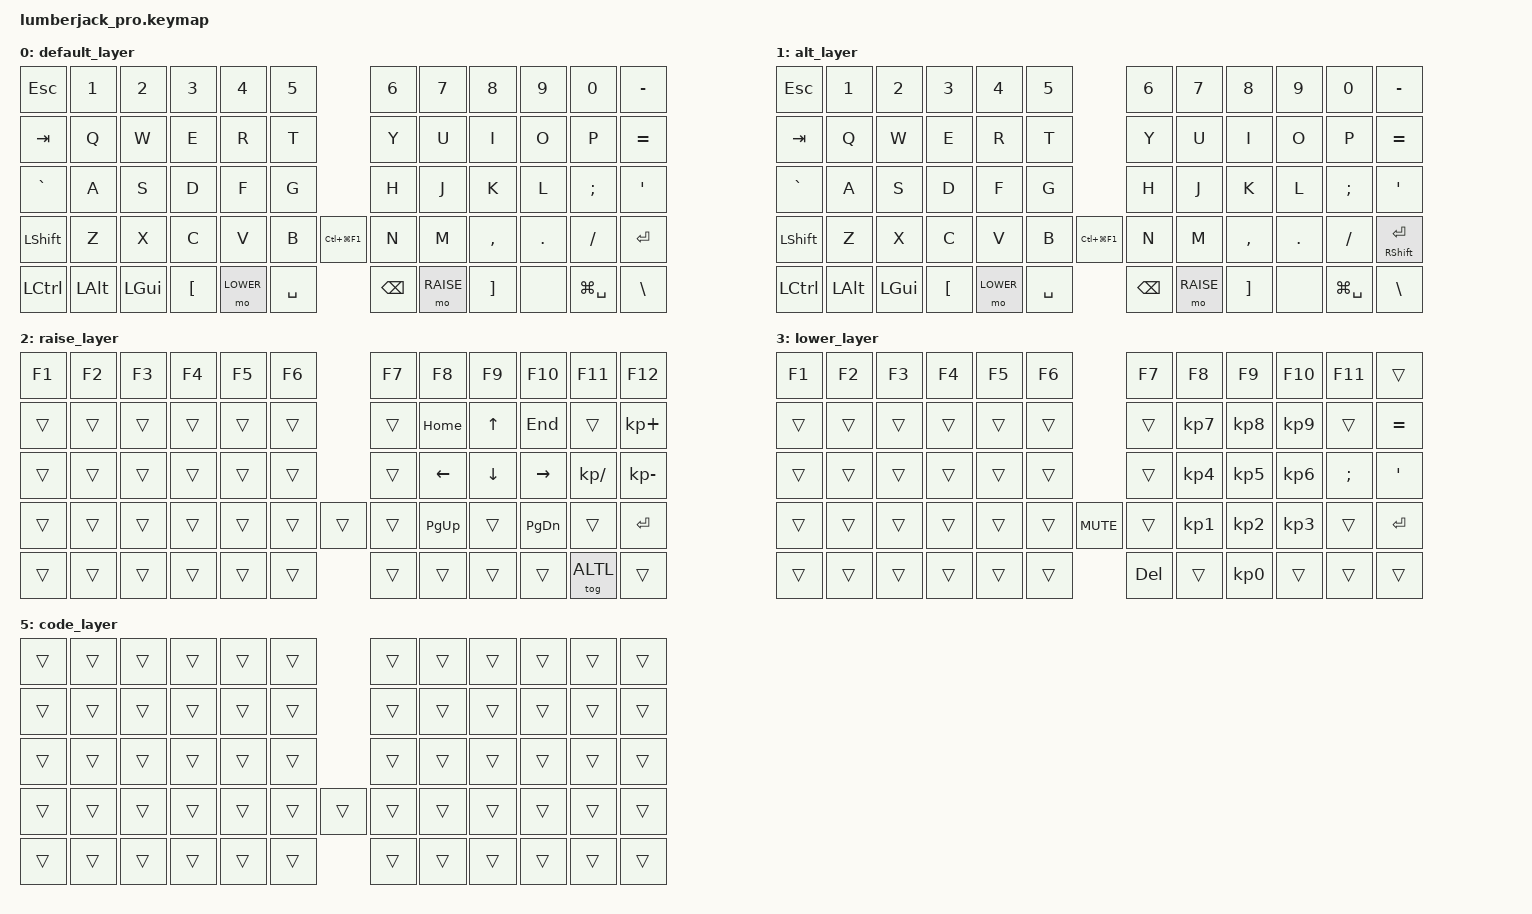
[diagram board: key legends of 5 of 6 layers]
/*
 * Copyright (c) 2021 The ZMK Contributors
 *
 * SPDX-License-Identifier: MIT
 */

#include <behaviors.dtsi>
#include <dt-bindings/zmk/keys.h>
#include <dt-bindings/zmk/bt.h>
#include <dt-bindings/zmk/outputs.h>
#include <dt-bindings/zmk/rgb.h>
#include <dt-bindings/zmk/ext_power.h>

#define BASE 0
#define ALTL 1
#define RAISE 2
#define LOWER 3
#define ADJUST 4
#define CODE 5


/* Uncomment to enable the encoder */
 &sensors {
     status = "okay";
 };
 &encoder { status = "okay"; };

 / {
    behaviors {
        mt: mod_tap {
            compatible = "zmk,behavior-hold-tap";
            #binding-cells = <2>;
            tapping-term-ms = <200>;
            flavor = "tap-preferred";
            bindings = <&kp>, <&kp>;
        };
    };
 };

/ {

    conditional_layers {
        compatible = "zmk,conditional-layers";
        adjust_layer {
            if-layers = <LOWER RAISE>;
            then-layer = <ADJUST>;
        };
    };

    keymap {
        compatible = "zmk,keymap";

        default_layer {
            bindings = <
                &kp ESC        &kp N1       &kp N2      &kp N3    &kp N4     &kp N5                      &kp N6         &kp N7      &kp N8      &kp N9      &kp N0        &kp MINUS
                &kp TAB        &kp Q        &kp W       &kp E     &kp R      &kp T                       &kp Y          &kp U       &kp I       &kp O       &kp P         &kp EQUAL
                &kp GRAVE      &kp A        &kp S       &kp D     &kp F      &kp G                       &kp H          &kp J       &kp K       &kp L       &kp SEMI      &kp SQT
                &kp LSHFT      &kp Z        &kp X       &kp C     &kp V      &kp B      &kp LC(LG(F1))   &kp N          &kp M       &kp COMMA   &kp DOT     &kp FSLH      &kp RET
                &kp LCTRL      &kp LALT     &kp LGUI    &kp LBKT  &mo LOWER  &kp SPACE                   &kp BSPC       &mo RAISE   &kp RBKT    &none       &kp LG(SPACE) &kp BSLH
            >;

            sensor-bindings = <&inc_dec_kp RIGHT LEFT>;
        };

        alt_layer {
            bindings = <
                &kp ESC        &kp N1       &kp N2      &kp N3    &kp N4     &kp N5                      &kp N6         &kp N7      &kp N8      &kp N9      &kp N0        &kp MINUS
                &kp TAB        &kp Q        &kp W       &kp E     &kp R      &kp T                       &kp Y          &kp U       &kp I       &kp O       &kp P         &kp EQUAL
                &kp GRAVE      &kp A        &kp S       &kp D     &kp F      &kp G                       &kp H          &kp J       &kp K       &kp L       &kp SEMI      &kp SQT
                &kp LSHFT      &kp Z        &kp X       &kp C     &kp V      &kp B      &kp LC(LG(F1))   &kp N          &kp M       &kp COMMA   &kp DOT     &kp FSLH      &mt RSHFT RET
                &kp LCTRL      &kp LALT     &kp LGUI    &kp LBKT  &mo LOWER  &kp SPACE                   &kp BSPC       &mo RAISE   &kp RBKT    &none       &kp LG(SPACE) &kp BSLH
            >;

            sensor-bindings = <&inc_dec_kp RIGHT LEFT>;
        };

        raise_layer {
            bindings = <
                &kp F1       &kp F2         &kp F3         &kp F4         &kp F5   &kp F6             &kp F7   &kp F8      &kp F9     &kp F10     &kp F11        &kp F12
                &trans       &trans         &trans         &trans         &trans   &trans             &trans   &kp HOME    &kp UP     &kp END     &trans         &kp KP_PLUS
                &trans       &trans         &trans         &trans         &trans   &trans             &trans   &kp LEFT    &kp DOWN   &kp RIGHT   &kp KP_DIVIDE  &kp KP_MINUS
                &trans       &trans         &trans         &trans         &trans   &trans    &trans   &trans   &kp PG_UP   &trans     &kp PG_DN   &trans         &kp RET
                &trans       &trans         &trans         &trans         &trans   &trans             &trans   &trans      &trans     &trans      &tog ALTL      &trans
            >;

            sensor-bindings = <&inc_dec_kp PG_DN PG_UP>;
        };
        lower_layer {
            bindings = <
                &kp F1       &kp F2         &kp F3         &kp F4         &kp F5   &kp F6              &kp F7   &kp F8      &kp F9     &kp F10     &kp F11         &trans
                &trans       &trans         &trans         &trans         &trans   &trans              &trans   &kp KP_N7   &kp KP_N8  &kp KP_N9   &trans          &kp EQUAL
                &trans       &trans         &trans         &trans         &trans   &trans              &trans   &kp KP_N4   &kp KP_N5  &kp KP_N6   &kp SEMI        &kp SQT
                &trans       &trans         &trans         &trans         &trans   &trans  &kp C_MUTE  &trans   &kp KP_N1   &kp KP_N2  &kp KP_N3   &trans          &kp RET
                &trans       &trans         &trans         &trans         &trans   &trans              &kp DEL   &trans      &kp KP_N0  &trans      &trans          &trans
            >;

            sensor-bindings = <&inc_dec_kp C_VOL_UP C_VOL_DN>;
        };

        adjust_layer {
            bindings = <
                &kp F1       &kp F2         &kp F3         &kp F4         &kp F5   &kp F6             &kp F7   &kp F8      &kp F9     &kp F10     &kp F11   &kp F12
                &bt BT_CLR   &bt BT_SEL 0   &bt BT_SEL 1   &bt BT_SEL 2   &trans   &bt BT_CLR_ALL      &trans   &trans      &trans     &trans      &trans    &trans
                &trans       &trans         &trans          &trans       &trans   &trans              &trans   &trans      &trans     &trans      &trans    &trans
                &rgb_ug RGB_TOG  &rgb_ug RGB_BRD  &rgb_ug RGB_BRI         &rgb_ug RGB_EFF  &trans     &trans   &trans      &trans     &trans      &trans    &trans
                &trans       &trans         &trans         &trans         &trans   &trans             &trans   &trans      &trans     &trans      &trans    &trans
            >;
        };

        code_layer {
            bindings = <
                &trans       &trans       &trans       &trans       &trans       &trans                    &trans     &trans     &trans     &trans     &trans        &trans
                &trans       &trans       &trans       &trans       &trans       &trans                    &trans     &trans     &trans     &trans     &trans        &trans
                &trans       &trans       &trans       &trans       &trans       &trans                    &trans     &trans     &trans     &trans     &trans        &trans
                &trans       &trans       &trans       &trans       &trans       &trans       &trans       &trans     &trans     &trans     &trans     &trans        &trans
                &trans       &trans       &trans       &trans       &trans       &trans                    &trans     &trans     &trans     &trans     &trans        &trans
            >;
        };
    };
};
